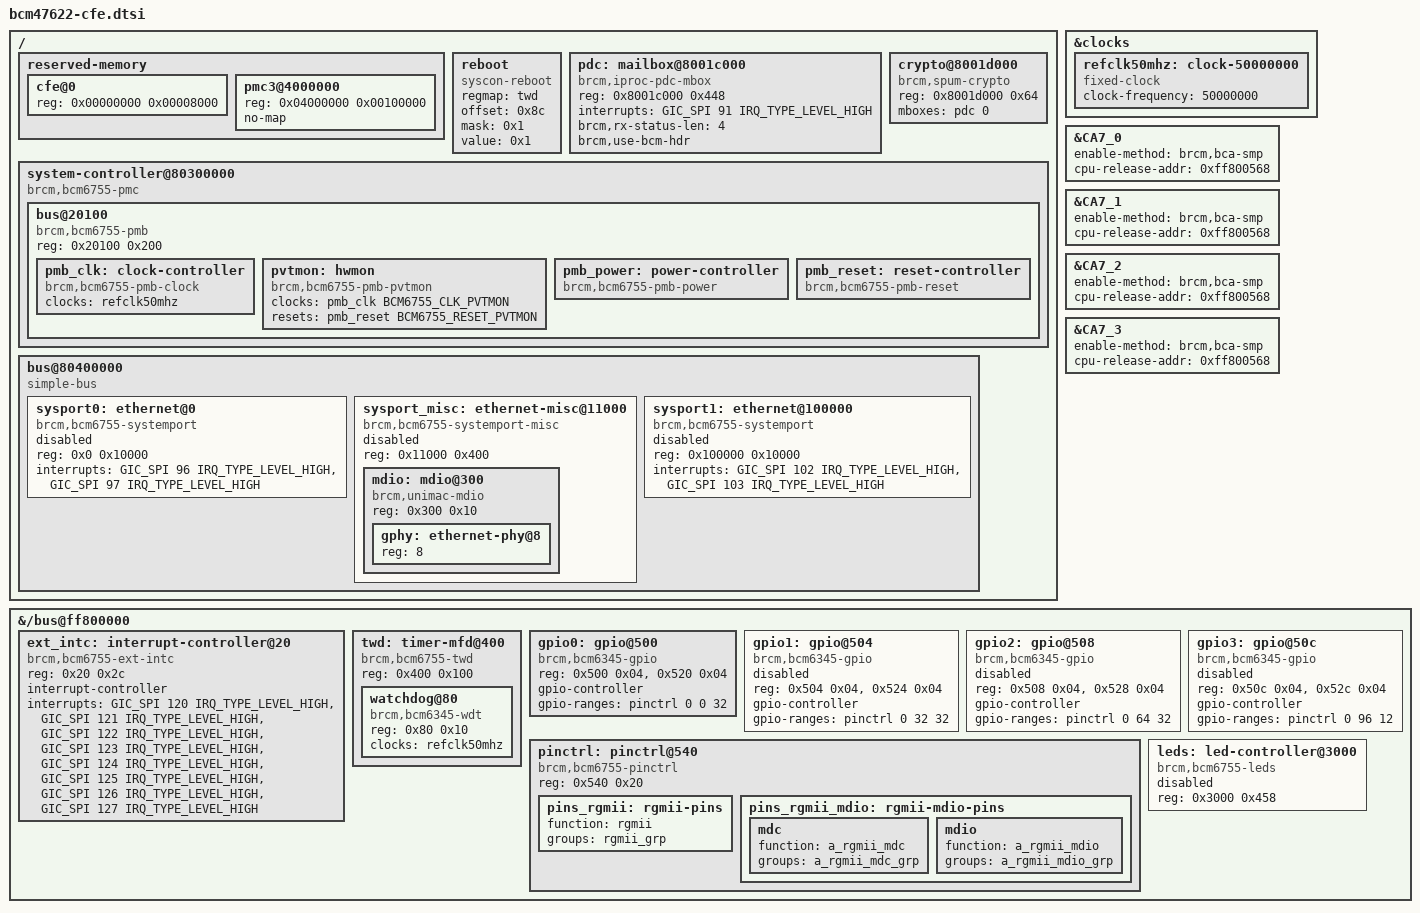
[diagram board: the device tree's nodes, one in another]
// SPDX-License-Identifier: GPL-2.0-or-later OR MIT
/*
 * BCM47622 / BCM6755 SoC additions on top of the upstream dtsi, for
 * devices booted by Broadcom CFE (no PSCI firmware).
 */

#include "broadcom/bcm47622.dtsi"

#include <dt-bindings/clock/brcm,bcm6755-pmb.h>
#include <dt-bindings/reset/brcm,bcm6755-pmb.h>

/ {
	/delete-node/ psci;

	reserved-memory {
		#address-cells = <1>;
		#size-cells = <1>;
		ranges;

		/*
		 * Reserved like the stock DTB's /memreserve/ does: the secondary
		 * CPUs wait in CFE's trampoline at 0x1000 until they are released
		 * to the kernel.
		 */
		cfe@0 {
			reg = <0x00000000 0x00008000>;
		};

		/* PMC3 firmware */
		pmc3@4000000 {
			reg = <0x04000000 0x00100000>;
			no-map;
		};
	};

	reboot {
		compatible = "syscon-reboot";
		regmap = <&twd>;
		/* WDTIMER0 WDTimerCtl: SOFT_RESET */
		offset = <0x8c>;
		mask = <0x1>;
		value = <0x1>;
	};

	/* SPU crypto engine and its DMA ring manager */
	pdc: mailbox@8001c000 {
		compatible = "brcm,iproc-pdc-mbox";
		reg = <0x8001c000 0x448>;
		interrupts = <GIC_SPI 91 IRQ_TYPE_LEVEL_HIGH>;
		#mbox-cells = <1>;
		brcm,rx-status-len = <4>;
		brcm,use-bcm-hdr;
	};

	crypto@8001d000 {
		compatible = "brcm,spum-crypto";
		reg = <0x8001d000 0x64>;
		mboxes = <&pdc 0>;
	};

	/* PMC3 complex; the Power Management Bus is in Procmon */
	system-controller@80300000 {
		compatible = "brcm,bcm6755-pmc", "simple-mfd";
		ranges = <0x0 0x80300000 0x21000>;
		#address-cells = <1>;
		#size-cells = <1>;

		bus@20100 {
			compatible = "brcm,bcm6755-pmb";
			reg = <0x20100 0x200>;

			pmb_clk: clock-controller {
				compatible = "brcm,bcm6755-pmb-clock";
				clocks = <&refclk50mhz>;
				clock-names = "ref";
				#clock-cells = <1>;
			};

			pvtmon: hwmon {
				compatible = "brcm,bcm6755-pmb-pvtmon";
				clocks = <&pmb_clk BCM6755_CLK_PVTMON>;
				resets = <&pmb_reset BCM6755_RESET_PVTMON>;
				#thermal-sensor-cells = <0>;
			};

			pmb_power: power-controller {
				compatible = "brcm,bcm6755-pmb-power";
				#power-domain-cells = <1>;
			};

			pmb_reset: reset-controller {
				compatible = "brcm,bcm6755-pmb-reset";
				#reset-cells = <1>;
			};
		};
	};

	bus@80400000 {
		compatible = "simple-bus";
		#address-cells = <1>;
		#size-cells = <1>;
		ranges = <0x0 0x80400000 0x120000>;

		sysport0: ethernet@0 {
			compatible = "brcm,bcm6755-systemport", "brcm,bcmbca-systemport-v2.0";
			reg = <0x0 0x10000>;
			/* SYSPORT0_0 (RX), SYSPORT0_1 (TX) */
			interrupts = <GIC_SPI 96 IRQ_TYPE_LEVEL_HIGH>,
				     <GIC_SPI 97 IRQ_TYPE_LEVEL_HIGH>;
			status = "disabled";
		};

		sysport_misc: ethernet-misc@11000 {
			compatible = "brcm,bcm6755-systemport-misc";
			reg = <0x11000 0x400>;
			#address-cells = <1>;
			#size-cells = <1>;
			ranges = <0x0 0x11000 0x400>;
			status = "disabled";

			mdio: mdio@300 {
				compatible = "brcm,unimac-mdio";
				reg = <0x300 0x10>;
				#address-cells = <1>;
				#size-cells = <0>;

				gphy: ethernet-phy@8 {
					reg = <8>;
				};
			};
		};

		sysport1: ethernet@100000 {
			compatible = "brcm,bcm6755-systemport", "brcm,bcmbca-systemport-v2.0";
			reg = <0x100000 0x10000>;
			/* SYSPORT1_0 (RX), SYSPORT1_1 (TX) */
			interrupts = <GIC_SPI 102 IRQ_TYPE_LEVEL_HIGH>,
				     <GIC_SPI 103 IRQ_TYPE_LEVEL_HIGH>;
			status = "disabled";
		};
	};
};

&clocks {
	/* 50 MHz crystal */
	refclk50mhz: clock-50000000 {
		compatible = "fixed-clock";
		#clock-cells = <0>;
		clock-frequency = <50000000>;
	};
};

/*
 * CFE parks the secondary cores in WFI; they jump to the address written to
 * the GPIO GeneralPurpose register (0xff800568) once woken up by an SGI.
 */
&CA7_0 {
	enable-method = "brcm,bca-smp";
	cpu-release-addr = <0xff800568>;
};

&CA7_1 {
	enable-method = "brcm,bca-smp";
	cpu-release-addr = <0xff800568>;
};

&CA7_2 {
	enable-method = "brcm,bca-smp";
	cpu-release-addr = <0xff800568>;
};

&CA7_3 {
	enable-method = "brcm,bca-smp";
	cpu-release-addr = <0xff800568>;
};

&{/bus@ff800000} {
	/* The interrupt specifier is <GPIO number, trigger type> */
	ext_intc: interrupt-controller@20 {
		compatible = "brcm,bcm6755-ext-intc", "brcm,bcmbca-ext-intc";
		reg = <0x20 0x2c>;
		interrupt-controller;
		#interrupt-cells = <2>;
		interrupts = <GIC_SPI 120 IRQ_TYPE_LEVEL_HIGH>,
			     <GIC_SPI 121 IRQ_TYPE_LEVEL_HIGH>,
			     <GIC_SPI 122 IRQ_TYPE_LEVEL_HIGH>,
			     <GIC_SPI 123 IRQ_TYPE_LEVEL_HIGH>,
			     <GIC_SPI 124 IRQ_TYPE_LEVEL_HIGH>,
			     <GIC_SPI 125 IRQ_TYPE_LEVEL_HIGH>,
			     <GIC_SPI 126 IRQ_TYPE_LEVEL_HIGH>,
			     <GIC_SPI 127 IRQ_TYPE_LEVEL_HIGH>;
	};

	twd: timer-mfd@400 {
		compatible = "brcm,bcm6755-twd", "simple-mfd", "syscon";
		reg = <0x400 0x100>;
		ranges = <0x0 0x400 0x100>;
		#address-cells = <1>;
		#size-cells = <1>;

		watchdog@80 {
			compatible = "brcm,bcm6345-wdt";
			reg = <0x80 0x10>;
			clocks = <&refclk50mhz>;
		};
	};

	/* GPIOs 0 .. 31 */
	gpio0: gpio@500 {
		compatible = "brcm,bcm6345-gpio";
		reg = <0x500 0x04>, <0x520 0x04>;
		reg-names = "dirout", "dat";
		gpio-controller;
		#gpio-cells = <2>;
		gpio-ranges = <&pinctrl 0 0 32>;
	};

	/* GPIOs 32 .. 63 */
	gpio1: gpio@504 {
		compatible = "brcm,bcm6345-gpio";
		reg = <0x504 0x04>, <0x524 0x04>;
		reg-names = "dirout", "dat";
		gpio-controller;
		#gpio-cells = <2>;
		gpio-ranges = <&pinctrl 0 32 32>;
		status = "disabled";
	};

	/* GPIOs 64 .. 95 */
	gpio2: gpio@508 {
		compatible = "brcm,bcm6345-gpio";
		reg = <0x508 0x04>, <0x528 0x04>;
		reg-names = "dirout", "dat";
		gpio-controller;
		#gpio-cells = <2>;
		gpio-ranges = <&pinctrl 0 64 32>;
		status = "disabled";
	};

	/* GPIOs 96 .. 107 */
	gpio3: gpio@50c {
		compatible = "brcm,bcm6345-gpio";
		reg = <0x50c 0x04>, <0x52c 0x04>;
		reg-names = "dirout", "dat";
		gpio-controller;
		#gpio-cells = <2>;
		gpio-ranges = <&pinctrl 0 96 12>;
		status = "disabled";
	};

	pinctrl: pinctrl@540 {
		compatible = "brcm,bcm6755-pinctrl";
		reg = <0x540 0x20>;

		pins_rgmii: rgmii-pins {
			function = "rgmii";
			groups = "rgmii_grp";
		};

		pins_rgmii_mdio: rgmii-mdio-pins {
			mdc {
				function = "a_rgmii_mdc";
				groups = "a_rgmii_mdc_grp";
			};

			mdio {
				function = "a_rgmii_mdio";
				groups = "a_rgmii_mdio_grp";
			};
		};
	};

	leds: led-controller@3000 {
		compatible = "brcm,bcm6755-leds";
		reg = <0x3000 0x458>;
		#address-cells = <1>;
		#size-cells = <0>;
		status = "disabled";
	};
};
